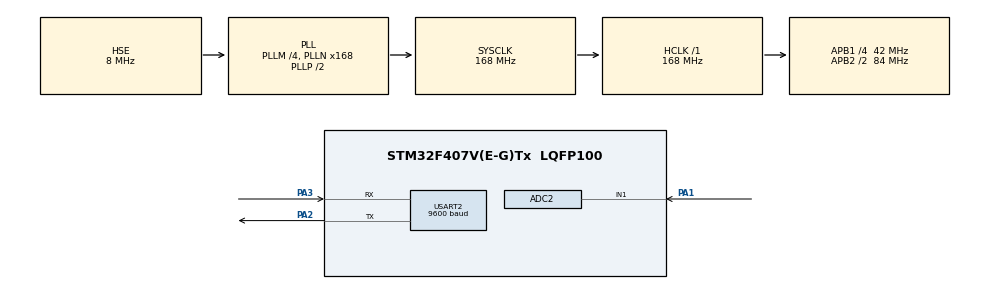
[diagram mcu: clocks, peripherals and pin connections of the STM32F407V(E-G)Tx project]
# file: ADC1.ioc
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ADC2.Channel-0\#ChannelRegularConversion=ADC_CHANNEL_1
ADC2.ContinuousConvMode=ENABLE
ADC2.EOCSelection=ADC_EOC_SEQ_CONV
ADC2.InjNumberOfConversion=0
ADC2.NbrOfConversion=1
ADC2.NbrOfConversionFlag=1
ADC2.Rank-0\#ChannelRegularConversion=1
ADC2.SamplingTime-0\#ChannelRegularConversion=ADC_SAMPLETIME_56CYCLES
ADC2.ScanConvMode=DISABLE
Mcu.Family=STM32F4
Mcu.Name=STM32F407V(E-G)Tx
Mcu.Package=LQFP100
NVIC.ADC_IRQn=true\:0\:0\:false\:false\:true\:true
NVIC.PriorityGroup=NVIC_PRIORITYGROUP_4
NVIC.USART2_IRQn=true\:0\:0\:false\:false\:true\:true
PA1.Signal=ADCx_IN1
PA13.Mode=Serial_Wire
PA13.Signal=SYS_JTMS-SWDIO
PA14.Mode=Serial_Wire
PA14.Signal=SYS_JTCK-SWCLK
PA2.Mode=Asynchronous
PA2.Signal=USART2_TX
PA3.Mode=Asynchronous
PA3.Signal=USART2_RX
PH0-OSC_IN.Mode=HSE-External-Oscillator
PH0-OSC_IN.Signal=RCC_OSC_IN
PH1-OSC_OUT.Mode=HSE-External-Oscillator
PH1-OSC_OUT.Signal=RCC_OSC_OUT
ProjectManager.HeapSize=0x200
ProjectManager.StackSize=0x400
ProjectManager.TargetToolchain=TrueSTUDIO
RCC.48MHZClocksFreq_Value=84000000
RCC.AHBFreq_Value=168000000
RCC.APB1CLKDivider=RCC_HCLK_DIV4
RCC.APB1Freq_Value=42000000
RCC.APB1TimFreq_Value=84000000
RCC.APB2CLKDivider=RCC_HCLK_DIV2
RCC.APB2Freq_Value=84000000
RCC.APB2TimFreq_Value=168000000
RCC.CortexFreq_Value=168000000
RCC.HCLKFreq_Value=168000000
RCC.HSE_VALUE=8000000
RCC.HSI_VALUE=16000000
RCC.LSE_VALUE=32768
RCC.PLLM=4
RCC.PLLN=168
RCC.PLLSourceVirtual=RCC_PLLSOURCE_HSE
RCC.SYSCLKFreq_VALUE=168000000
RCC.SYSCLKSource=RCC_SYSCLKSOURCE_PLLCLK
RCC.VCOOutputFreq_Value=336000000
SH.ADCx_IN1.0=ADC2_IN1,IN1
USART2.BaudRate=9600
USART2.VirtualMode=VM_ASYNC
board=ADC1

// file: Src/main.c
/**
  ******************************************************************************
  * File Name          : main.c
  * Description        : Main program body
  ******************************************************************************
  ** This notice applies to any and all portions of this file
  * that are not between comment pairs USER CODE BEGIN and
  * USER CODE END. Other portions of this file, whether
  * inserted by the user or by software development tools
  * are owned by their respective copyright owners.
  *
  * COPYRIGHT(c) 2018 STMicroelectronics
  *
  * Redistribution and use in source and binary forms, with or without modification,
  * are permitted provided that the following conditions are met:
  *   1. Redistributions of source code must retain the above copyright notice,
  *      this list of conditions and the following disclaimer.
  *   2. Redistributions in binary form must reproduce the above copyright notice,
  *      this list of conditions and the following disclaimer in the documentation
  *      and/or other materials provided with the distribution.
  *   3. Neither the name of STMicroelectronics nor the names of its contributors
  *      may be used to endorse or promote products derived from this software
  *      without specific prior written permission.
  *
  * THIS SOFTWARE IS PROVIDED BY THE COPYRIGHT HOLDERS AND CONTRIBUTORS "AS IS"
  * AND ANY EXPRESS OR IMPLIED WARRANTIES, INCLUDING, BUT NOT LIMITED TO, THE
  * IMPLIED WARRANTIES OF MERCHANTABILITY AND FITNESS FOR A PARTICULAR PURPOSE ARE
  * DISCLAIMED. IN NO EVENT SHALL THE COPYRIGHT HOLDER OR CONTRIBUTORS BE LIABLE
  * FOR ANY DIRECT, INDIRECT, INCIDENTAL, SPECIAL, EXEMPLARY, OR CONSEQUENTIAL
  * DAMAGES (INCLUDING, BUT NOT LIMITED TO, PROCUREMENT OF SUBSTITUTE GOODS OR
  * SERVICES; LOSS OF USE, DATA, OR PROFITS; OR BUSINESS INTERRUPTION) HOWEVER
  * CAUSED AND ON ANY THEORY OF LIABILITY, WHETHER IN CONTRACT, STRICT LIABILITY,
  * OR TORT (INCLUDING NEGLIGENCE OR OTHERWISE) ARISING IN ANY WAY OUT OF THE USE
  * OF THIS SOFTWARE, EVEN IF ADVISED OF THE POSSIBILITY OF SUCH DAMAGE.
  *
  ******************************************************************************
  */

#include "main.h"
#include "stm32f4xx_hal.h"

ADC_HandleTypeDef hadc2;

UART_HandleTypeDef huart2;

/* USER CODE BEGIN PV */
/* Private variables ---------------------------------------------------------*/
uint32_t v_adcValue_u32=0;
uint8_t buf[5];
/* USER CODE END PV */

void SystemClock_Config(void);
static void MX_GPIO_Init(void);
static void MX_ADC2_Init(void);
static void MX_USART2_UART_Init(void);

/* USER CODE BEGIN PFP */
/* Private function prototypes -----------------------------------------------*/

/* USER CODE END PFP */

/* USER CODE BEGIN 0 */
void HAL_UART_TxCpltCallback(UART_HandleTypeDef *huart)
{

}

void GetNumtoString(uint32_t v_counter_u32)
{
		 buf[3] = 48 + ((v_counter_u32 / 1) - ((v_counter_u32 / 10) * 10));
		 buf[2] = 48 + ((v_counter_u32 / 10) - ((v_counter_u32 / 100) * 10));
		 buf[1] = 48 + ((v_counter_u32 / 100) - ((v_counter_u32 / 1000) * 10));
		 buf[0] = 48 + ((v_counter_u32 / 1000) - ((v_counter_u32 / 10000) * 10));
		 buf[4] = 10;

}
/* USER CODE END 0 */

int main(void)
{

  /* MCU Configuration----------------------------------------------------------*/

  /* Reset of all peripherals, Initializes the Flash interface and the Systick. */
  HAL_Init();

  /* Configure the system clock */
  SystemClock_Config();

  /* Initialize all configured peripherals */
  MX_GPIO_Init();
  MX_ADC2_Init();
  MX_USART2_UART_Init();

  /* USER CODE BEGIN 2 */
  HAL_ADC_Start(&hadc2);

  /* USER CODE END 2 */

  /* Infinite loop */
  while (1)
  {

  /* USER CODE BEGIN 3 */
	  HAL_ADC_PollForConversion(&hadc2,8);
	  v_adcValue_u32 = HAL_ADC_GetValue(&hadc2);
	  GetNumtoString(v_adcValue_u32);
	  HAL_UART_Transmit_IT(&huart2,(uint8_t *)&buf,sizeof(buf));
  }
  /* USER CODE END 3 */

}

/** System Clock Configuration
*/
void SystemClock_Config(void)
{

  RCC_OscInitTypeDef RCC_OscInitStruct;
  RCC_ClkInitTypeDef RCC_ClkInitStruct;

    /**Configure the main internal regulator output voltage
    */
  __HAL_RCC_PWR_CLK_ENABLE();

  __HAL_PWR_VOLTAGESCALING_CONFIG(PWR_REGULATOR_VOLTAGE_SCALE1);

    /**Initializes the CPU, AHB and APB busses clocks
    */
  RCC_OscInitStruct.OscillatorType = RCC_OSCILLATORTYPE_HSE;
  RCC_OscInitStruct.HSEState = RCC_HSE_ON;
  RCC_OscInitStruct.PLL.PLLState = RCC_PLL_ON;
  RCC_OscInitStruct.PLL.PLLSource = RCC_PLLSOURCE_HSE;
  RCC_OscInitStruct.PLL.PLLM = 4;
  RCC_OscInitStruct.PLL.PLLN = 168;
  RCC_OscInitStruct.PLL.PLLP = RCC_PLLP_DIV2;
  RCC_OscInitStruct.PLL.PLLQ = 4;
  if (HAL_RCC_OscConfig(&RCC_OscInitStruct) != HAL_OK)
  {
    _Error_Handler(__FILE__, __LINE__);
  }

    /**Initializes the CPU, AHB and APB busses clocks
    */
  RCC_ClkInitStruct.ClockType = RCC_CLOCKTYPE_HCLK|RCC_CLOCKTYPE_SYSCLK
                              |RCC_CLOCKTYPE_PCLK1|RCC_CLOCKTYPE_PCLK2;
  RCC_ClkInitStruct.SYSCLKSource = RCC_SYSCLKSOURCE_PLLCLK;
  RCC_ClkInitStruct.AHBCLKDivider = RCC_SYSCLK_DIV1;
  RCC_ClkInitStruct.APB1CLKDivider = RCC_HCLK_DIV4;
  RCC_ClkInitStruct.APB2CLKDivider = RCC_HCLK_DIV2;

  if (HAL_RCC_ClockConfig(&RCC_ClkInitStruct, FLASH_LATENCY_5) != HAL_OK)
  {
    _Error_Handler(__FILE__, __LINE__);
  }

    /**Configure the Systick interrupt time
    */
  HAL_SYSTICK_Config(HAL_RCC_GetHCLKFreq()/1000);

    /**Configure the Systick
    */
  HAL_SYSTICK_CLKSourceConfig(SYSTICK_CLKSOURCE_HCLK);

  /* SysTick_IRQn interrupt configuration */
  HAL_NVIC_SetPriority(SysTick_IRQn, 0, 0);
}

/* ADC2 init function */
static void MX_ADC2_Init(void)
{

  ADC_ChannelConfTypeDef sConfig;

    /**Configure the global features of the ADC (Clock, Resolution, Data Alignment and number of conversion)
    */
  hadc2.Instance = ADC2;
  hadc2.Init.ClockPrescaler = ADC_CLOCK_SYNC_PCLK_DIV4;
  hadc2.Init.Resolution = ADC_RESOLUTION_12B;
  hadc2.Init.ScanConvMode = DISABLE;
  hadc2.Init.ContinuousConvMode = ENABLE;
  hadc2.Init.DiscontinuousConvMode = DISABLE;
  hadc2.Init.ExternalTrigConvEdge = ADC_EXTERNALTRIGCONVEDGE_NONE;
  hadc2.Init.ExternalTrigConv = ADC_SOFTWARE_START;
  hadc2.Init.DataAlign = ADC_DATAALIGN_RIGHT;
  hadc2.Init.NbrOfConversion = 1;
  hadc2.Init.DMAContinuousRequests = DISABLE;
  hadc2.Init.EOCSelection = ADC_EOC_SEQ_CONV;
  if (HAL_ADC_Init(&hadc2) != HAL_OK)
  {
    _Error_Handler(__FILE__, __LINE__);
  }

    /**Configure for the selected ADC regular channel its corresponding rank in the sequencer and its sample time.
    */
  sConfig.Channel = ADC_CHANNEL_1;
  sConfig.Rank = 1;
  sConfig.SamplingTime = ADC_SAMPLETIME_56CYCLES;
  if (HAL_ADC_ConfigChannel(&hadc2, &sConfig) != HAL_OK)
  {
    _Error_Handler(__FILE__, __LINE__);
  }

}

/* USART2 init function */
static void MX_USART2_UART_Init(void)
{

  huart2.Instance = USART2;
  huart2.Init.BaudRate = 9600;
  huart2.Init.WordLength = UART_WORDLENGTH_8B;
  huart2.Init.StopBits = UART_STOPBITS_1;
  huart2.Init.Parity = UART_PARITY_NONE;
  huart2.Init.Mode = UART_MODE_TX_RX;
  huart2.Init.HwFlowCtl = UART_HWCONTROL_NONE;
  huart2.Init.OverSampling = UART_OVERSAMPLING_16;
  if (HAL_UART_Init(&huart2) != HAL_OK)
  {
    _Error_Handler(__FILE__, __LINE__);
  }

}

/** Configure pins as
        * Analog
        * Input
        * Output
        * EVENT_OUT
        * EXTI
*/
static void MX_GPIO_Init(void)
{

  /* GPIO Ports Clock Enable */
  __HAL_RCC_GPIOH_CLK_ENABLE();
  __HAL_RCC_GPIOA_CLK_ENABLE();

}

void _Error_Handler(char * file, int line)
{
  while(1)
  {
  }
}

/************************ (C) COPYRIGHT STMicroelectronics *****END OF FILE****/
